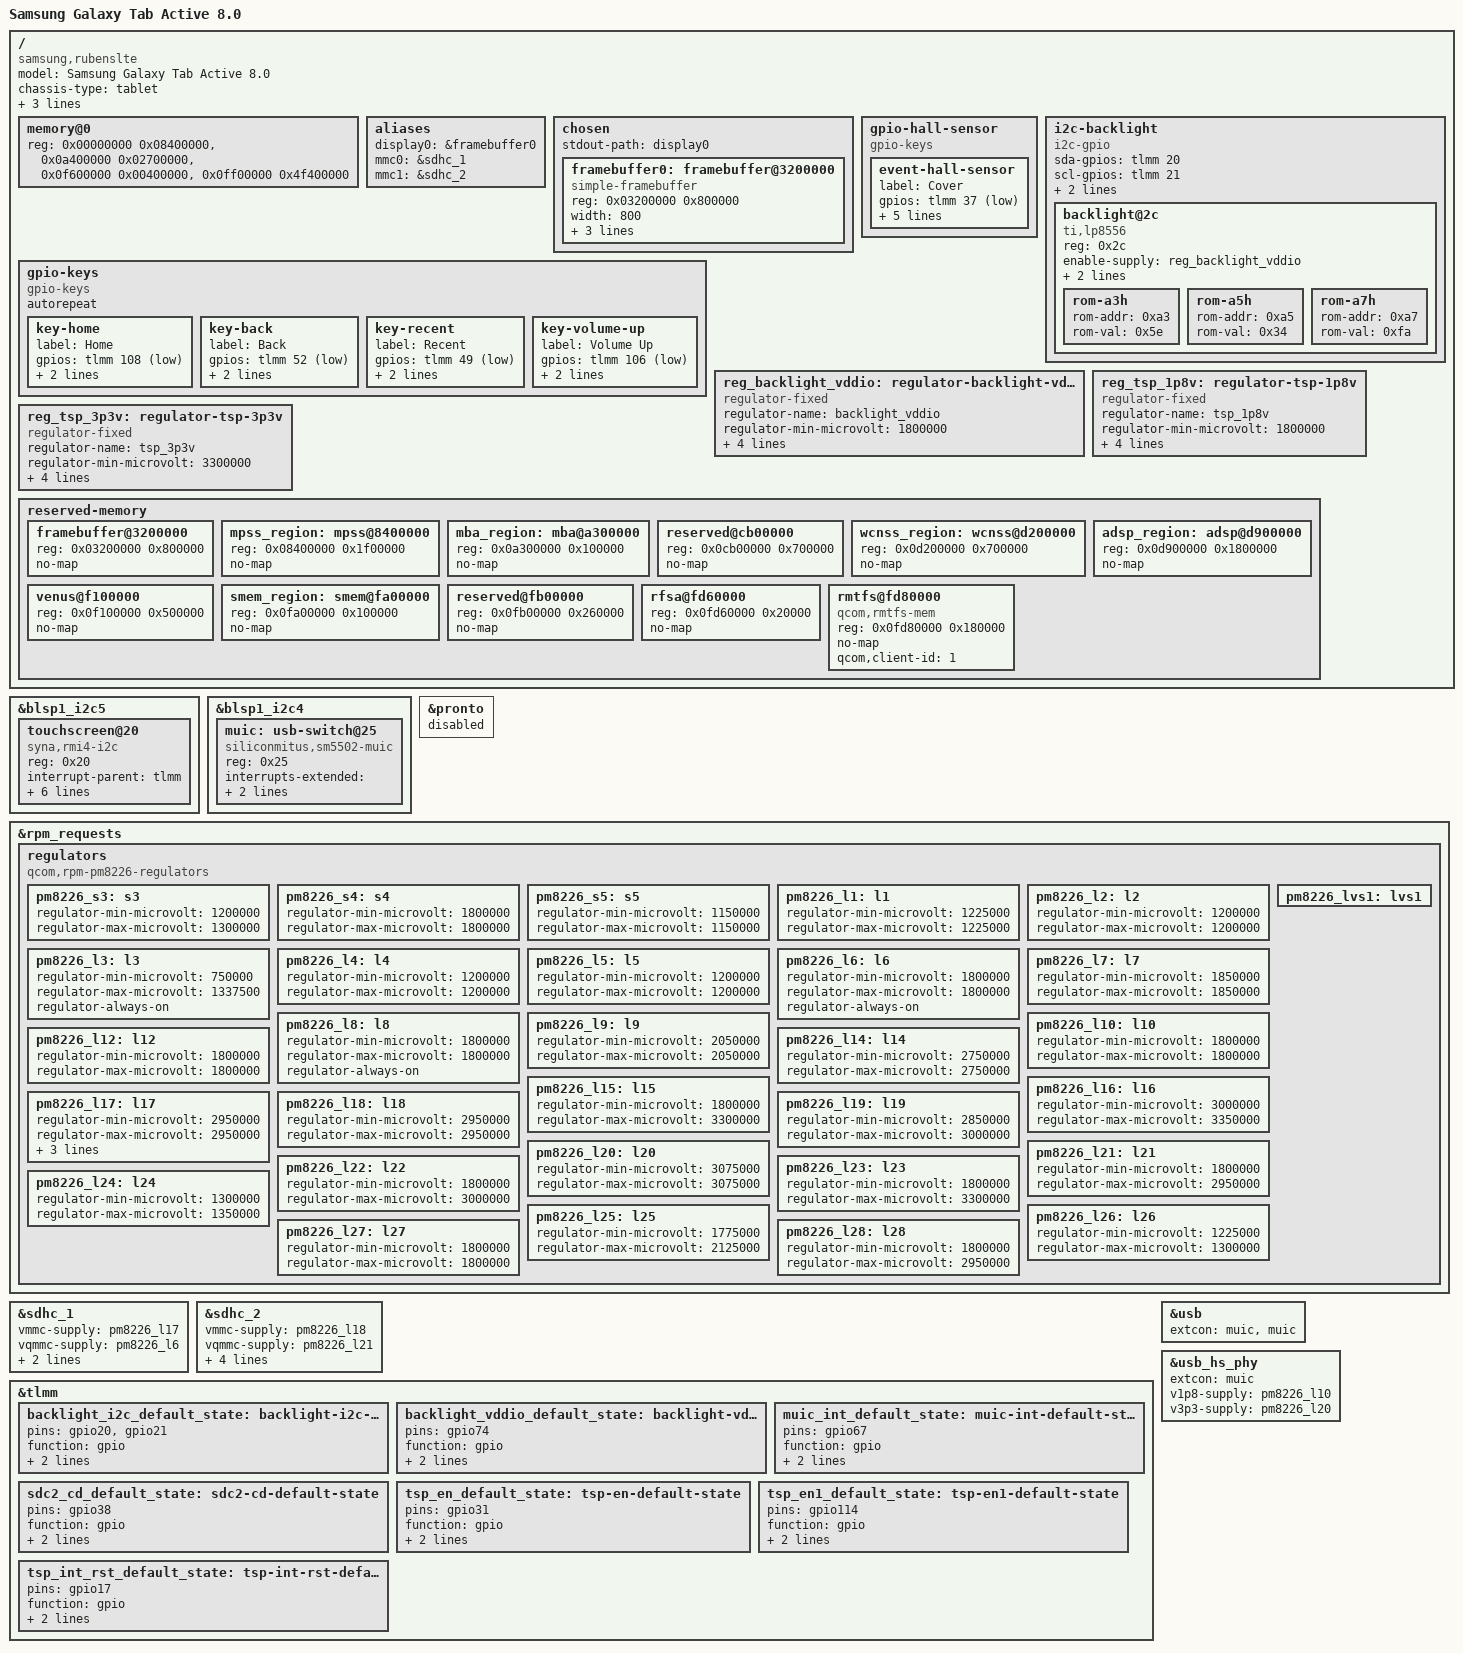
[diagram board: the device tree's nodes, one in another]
// SPDX-License-Identifier: BSD-3-Clause
/*
 * Samsung Galaxy Tab Active 8.0 (SM-T360 / SM-T365), codename "rubens".
 *
 * Derived from qcom-apq8026-samsung-milletwifi.dts (Tab 4 8.0, same APQ8026,
 * same 800x1280 panel class, same LP8556 backlight and touch enables).
 * Device-specific values taken from Samsung's downstream tree:
 *   msm8926-sec-rubenslteeur-r03.dtsi and
 *   dsi_panel_sdc_wxga_video_rubenslte.dtsi
 * and from the running device (dmesg / proc):
 *   panel  mdss_dsi_sdc_wxga_video_lte, 800x1280, S6D7AA0
 *   touch  synaptics rmi4 @ i2c5 0x20, irq gpio17, en gpio31 + gpio114, RUBENS
 *   fb     aboot reserved EBI1 0x800000 @ 0x03200000
 *
 * STATUS: phase 1 (simple-framebuffer + RMI4 touch + eMMC/SD + keys).
 * Not yet compiled - needs a dtc pass in CI. Nodes marked FIXME are unverified.
 */

/dts-v1/;

#include <dt-bindings/gpio/gpio.h>
#include <dt-bindings/input/input.h>
#include <dt-bindings/interrupt-controller/irq.h>
#include "qcom-msm8226.dtsi"
#include "pm8226.dtsi"

/delete-node/ &adsp_region;
/delete-node/ &mba_region;
/delete-node/ &mpss_region;
/delete-node/ &smem_region;
/delete-node/ &wcnss_region;

/ {
	model = "Samsung Galaxy Tab Active 8.0";
	compatible = "samsung,rubenslte", "qcom,apq8026";
	chassis-type = "tablet";

	/*
	 * Copied verbatim from this tablet's factory DTB (RUBENS-WIFI-EUR-OPEN
	 * Rev-02, variant 2). Samsung's aboot matches its QCDT table on these
	 * triples; without the property the bootloader has nothing to match.
	 */
	qcom,msm-id = <0xc708ff01 0x2 0x20000>,
		      <0xc708ff01 0x3 0x20000>,
		      <0xc708ff01 0x4 0x20000>;

	/*
	 * qcom-msm8226.dtsi only carries a placeholder (reg = <0x0 0x0>), so
	 * without this the kernel is told it has no RAM and hangs silently
	 * before printing anything. These four ranges are the System RAM
	 * entries of this tablet's live /proc/iomem, read in TWRP:
	 *   00000000-083fffff  0a400000-0cafffff
	 *   0f600000-0f9fffff  0ff00000-5f2fffff
	 *
	 * The second range must be 0x02700000, not 0x02c00000: the larger size
	 * runs past 0x0cafffff into the wcnss/qseecom reserved regions and the
	 * kernel then owns memory the firmware is still using.
	 */
	memory@0 {
		device_type = "memory";
		reg = <0x00000000 0x08400000>,
		      <0x0a400000 0x02700000>,
		      <0x0f600000 0x00400000>,
		      <0x0ff00000 0x4f400000>;
	};

	aliases {
		display0 = &framebuffer0;
		mmc0 = &sdhc_1; /* SDC1 eMMC slot */
		mmc1 = &sdhc_2; /* SDC2 SD card slot */
	};

	chosen {
		#address-cells = <1>;
		#size-cells = <1>;
		ranges;

		stdout-path = "display0";

		framebuffer0: framebuffer@3200000 {
			compatible = "simple-framebuffer";
			reg = <0x03200000 0x800000>;
			width = <800>;
			height = <1280>;
			stride = <(800 * 3)>;
			format = "r8g8b8";
		};
	};

	gpio-hall-sensor {
		compatible = "gpio-keys";

		event-hall-sensor {
			label = "Cover";
			gpios = <&tlmm 37 GPIO_ACTIVE_LOW>;
			linux,input-type = <EV_SW>;
			linux,code = <SW_LID>;
			debounce-interval = <15>;
			linux,can-disable;
			wakeup-source;
		};
	};

	gpio-keys {
		compatible = "gpio-keys";
		autorepeat;

		key-home {
			label = "Home";
			gpios = <&tlmm 108 GPIO_ACTIVE_LOW>;
			linux,code = <KEY_HOMEPAGE>;
			debounce-interval = <15>;
		};

		key-back {
			label = "Back";
			gpios = <&tlmm 52 GPIO_ACTIVE_LOW>;
			linux,code = <KEY_BACK>;
			debounce-interval = <15>;
		};

		/* KEY_RECENT does not exist upstream; 254 is what Samsung used */
		key-recent {
			label = "Recent";
			gpios = <&tlmm 49 GPIO_ACTIVE_LOW>;
			linux,code = <254>;
			debounce-interval = <15>;
		};

		key-volume-up {
			label = "Volume Up";
			gpios = <&tlmm 106 GPIO_ACTIVE_LOW>;
			linux,code = <KEY_VOLUMEUP>;
			debounce-interval = <15>;
		};

		/*
		 * Volume Down is wired to the PMIC RESIN pin, not a TLMM GPIO
		 * (Samsung comments the node out in the downstream tree), so
		 * there is no gpio-keys entry for it here.
		 */
	};

	i2c-backlight {
		compatible = "i2c-gpio";
		sda-gpios = <&tlmm 20 (GPIO_ACTIVE_HIGH|GPIO_OPEN_DRAIN)>;
		scl-gpios = <&tlmm 21 (GPIO_ACTIVE_HIGH|GPIO_OPEN_DRAIN)>;

		pinctrl-0 = <&backlight_i2c_default_state>;
		pinctrl-names = "default";

		i2c-gpio,delay-us = <4>;

		#address-cells = <1>;
		#size-cells = <0>;

		backlight@2c {
			compatible = "ti,lp8556";
			reg = <0x2c>;
			enable-supply = <&reg_backlight_vddio>;

			dev-ctrl = /bits/ 8 <0x80>;
			init-brt = /bits/ 8 <0x3f>;

			rom-a3h {
				rom-addr = /bits/ 8 <0xa3>;
				rom-val = /bits/ 8 <0x5e>;
			};

			rom-a5h {
				rom-addr = /bits/ 8 <0xa5>;
				rom-val = /bits/ 8 <0x34>;
			};

			rom-a7h {
				rom-addr = /bits/ 8 <0xa7>;
				rom-val = /bits/ 8 <0xfa>;
			};
		};
	};

	reg_backlight_vddio: regulator-backlight-vddio {
		compatible = "regulator-fixed";
		regulator-name = "backlight_vddio";
		regulator-min-microvolt = <1800000>;
		regulator-max-microvolt = <1800000>;

		gpio = <&tlmm 74 GPIO_ACTIVE_HIGH>;
		enable-active-high;

		pinctrl-0 = <&backlight_vddio_default_state>;
		pinctrl-names = "default";
	};

	reg_tsp_1p8v: regulator-tsp-1p8v {
		compatible = "regulator-fixed";
		regulator-name = "tsp_1p8v";
		regulator-min-microvolt = <1800000>;
		regulator-max-microvolt = <1800000>;

		gpio = <&tlmm 114 GPIO_ACTIVE_HIGH>;
		enable-active-high;

		pinctrl-0 = <&tsp_en1_default_state>;
		pinctrl-names = "default";
	};

	reg_tsp_3p3v: regulator-tsp-3p3v {
		compatible = "regulator-fixed";
		regulator-name = "tsp_3p3v";
		regulator-min-microvolt = <3300000>;
		regulator-max-microvolt = <3300000>;

		gpio = <&tlmm 31 GPIO_ACTIVE_HIGH>;
		enable-active-high;

		pinctrl-0 = <&tsp_en_default_state>;
		pinctrl-names = "default";
	};

	reserved-memory {
		#address-cells = <1>;
		#size-cells = <1>;
		ranges;

		framebuffer@3200000 {
			reg = <0x03200000 0x800000>;
			no-map;
		};

		mpss_region: mpss@8400000 {
			reg = <0x08400000 0x1f00000>;
			no-map;
		};

		mba_region: mba@a300000 {
			reg = <0x0a300000 0x100000>;
			no-map;
		};

		reserved@cb00000 {
			reg = <0x0cb00000 0x700000>;
			no-map;
		};

		wcnss_region: wcnss@d200000 {
			reg = <0x0d200000 0x700000>;
			no-map;
		};

		adsp_region: adsp@d900000 {
			reg = <0x0d900000 0x1800000>;
			no-map;
		};

		venus@f100000 {
			reg = <0x0f100000 0x500000>;
			no-map;
		};

		smem_region: smem@fa00000 {
			reg = <0x0fa00000 0x100000>;
			no-map;
		};

		reserved@fb00000 {
			reg = <0x0fb00000 0x260000>;
			no-map;
		};

		rfsa@fd60000 {
			reg = <0x0fd60000 0x20000>;
			no-map;
		};

		rmtfs@fd80000 {
			compatible = "qcom,rmtfs-mem";
			reg = <0x0fd80000 0x180000>;
			no-map;

			qcom,client-id = <1>;
		};
	};
};

/*
 * Touch: Synaptics RMI4 (F12), 1599x2559 sensor reporting 800x1280.
 * Same bus and same enable rails as milletwifi, different controller.
 */
&blsp1_i2c5 {
	status = "okay";

	touchscreen@20 {
		compatible = "syna,rmi4-i2c";
		reg = <0x20>;

		interrupt-parent = <&tlmm>;
		interrupts = <17 IRQ_TYPE_EDGE_FALLING>;

		vdd-supply = <&reg_tsp_1p8v>;
		vio-supply = <&reg_tsp_3p3v>;

		syna,reset-delay-ms = <200>;
		syna,startup-delay-ms = <200>;

		pinctrl-0 = <&tsp_int_rst_default_state>;
		pinctrl-names = "default";
	};
};

/*
 * FIXME: MUIC. rubens uses the same PMIC/charger family as millet, but the
 * exact part and bus were not confirmed from the running device. USB stays
 * dead until this is verified; do not guess further than the sm5502 that the
 * sibling tablet uses.
 */
&blsp1_i2c4 {
	status = "okay";

	muic: usb-switch@25 {
		compatible = "siliconmitus,sm5502-muic";
		reg = <0x25>;

		interrupts-extended = <&tlmm 67 IRQ_TYPE_EDGE_FALLING>;

		pinctrl-0 = <&muic_int_default_state>;
		pinctrl-names = "default";
	};
};

/*
 * WCNSS (WiFi/BT) is left disabled on purpose: it needs the remoteproc
 * firmware pulled off the device's /firmware partition before it can do
 * anything, and upstream support is still WIP.
 */
&pronto {
	status = "disabled";
};

&rpm_requests {
	regulators {
		compatible = "qcom,rpm-pm8226-regulators";

		pm8226_s3: s3 {
			regulator-min-microvolt = <1200000>;
			regulator-max-microvolt = <1300000>;
		};

		pm8226_s4: s4 {
			regulator-min-microvolt = <1800000>;
			regulator-max-microvolt = <1800000>;
		};

		pm8226_s5: s5 {
			regulator-min-microvolt = <1150000>;
			regulator-max-microvolt = <1150000>;
		};

		pm8226_l1: l1 {
			regulator-min-microvolt = <1225000>;
			regulator-max-microvolt = <1225000>;
		};

		pm8226_l2: l2 {
			regulator-min-microvolt = <1200000>;
			regulator-max-microvolt = <1200000>;
		};

		pm8226_l3: l3 {
			regulator-min-microvolt = <750000>;
			regulator-max-microvolt = <1337500>;
			regulator-always-on;
		};

		pm8226_l4: l4 {
			regulator-min-microvolt = <1200000>;
			regulator-max-microvolt = <1200000>;
		};

		pm8226_l5: l5 {
			regulator-min-microvolt = <1200000>;
			regulator-max-microvolt = <1200000>;
		};

		pm8226_l6: l6 {
			regulator-min-microvolt = <1800000>;
			regulator-max-microvolt = <1800000>;
			regulator-always-on;
		};

		pm8226_l7: l7 {
			regulator-min-microvolt = <1850000>;
			regulator-max-microvolt = <1850000>;
		};

		pm8226_l8: l8 {
			regulator-min-microvolt = <1800000>;
			regulator-max-microvolt = <1800000>;
			regulator-always-on;
		};

		pm8226_l9: l9 {
			regulator-min-microvolt = <2050000>;
			regulator-max-microvolt = <2050000>;
		};

		pm8226_l10: l10 {
			regulator-min-microvolt = <1800000>;
			regulator-max-microvolt = <1800000>;
		};

		pm8226_l12: l12 {
			regulator-min-microvolt = <1800000>;
			regulator-max-microvolt = <1800000>;
		};

		pm8226_l14: l14 {
			regulator-min-microvolt = <2750000>;
			regulator-max-microvolt = <2750000>;
		};

		pm8226_l15: l15 {
			regulator-min-microvolt = <1800000>;
			regulator-max-microvolt = <3300000>;
		};

		pm8226_l16: l16 {
			regulator-min-microvolt = <3000000>;
			regulator-max-microvolt = <3350000>;
		};

		pm8226_l17: l17 {
			regulator-min-microvolt = <2950000>;
			regulator-max-microvolt = <2950000>;

			regulator-system-load = <200000>;
			regulator-allow-set-load;
			regulator-always-on;
		};

		pm8226_l18: l18 {
			regulator-min-microvolt = <2950000>;
			regulator-max-microvolt = <2950000>;
		};

		pm8226_l19: l19 {
			regulator-min-microvolt = <2850000>;
			regulator-max-microvolt = <3000000>;
		};

		pm8226_l20: l20 {
			regulator-min-microvolt = <3075000>;
			regulator-max-microvolt = <3075000>;
		};

		pm8226_l21: l21 {
			regulator-min-microvolt = <1800000>;
			regulator-max-microvolt = <2950000>;
		};

		pm8226_l22: l22 {
			regulator-min-microvolt = <1800000>;
			regulator-max-microvolt = <3000000>;
		};

		pm8226_l23: l23 {
			regulator-min-microvolt = <1800000>;
			regulator-max-microvolt = <3300000>;
		};

		pm8226_l24: l24 {
			regulator-min-microvolt = <1300000>;
			regulator-max-microvolt = <1350000>;
		};

		pm8226_l25: l25 {
			regulator-min-microvolt = <1775000>;
			regulator-max-microvolt = <2125000>;
		};

		pm8226_l26: l26 {
			regulator-min-microvolt = <1225000>;
			regulator-max-microvolt = <1300000>;
		};

		pm8226_l27: l27 {
			regulator-min-microvolt = <1800000>;
			regulator-max-microvolt = <1800000>;
		};

		pm8226_l28: l28 {
			regulator-min-microvolt = <1800000>;
			regulator-max-microvolt = <2950000>;
		};

		pm8226_lvs1: lvs1 {};
	};
};

&sdhc_1 {
	vmmc-supply = <&pm8226_l17>;
	vqmmc-supply = <&pm8226_l6>;

	bus-width = <8>;
	non-removable;

	status = "okay";
};

&sdhc_2 {
	vmmc-supply = <&pm8226_l18>;
	vqmmc-supply = <&pm8226_l21>;

	bus-width = <4>;
	cd-gpios = <&tlmm 38 GPIO_ACTIVE_LOW>;

	pinctrl-0 = <&sdhc2_default_state>, <&sdc2_cd_default_state>;
	pinctrl-names = "default";

	status = "okay";
};

&tlmm {
	backlight_i2c_default_state: backlight-i2c-default-state {
		pins = "gpio20", "gpio21";
		function = "gpio";
		drive-strength = <2>;
		bias-disable;
	};

	backlight_vddio_default_state: backlight-vddio-default-state {
		pins = "gpio74";
		function = "gpio";
		drive-strength = <2>;
		bias-disable;
	};

	muic_int_default_state: muic-int-default-state {
		pins = "gpio67";
		function = "gpio";
		drive-strength = <2>;
		bias-disable;
	};

	sdc2_cd_default_state: sdc2-cd-default-state {
		pins = "gpio38";
		function = "gpio";
		drive-strength = <2>;
		bias-disable;
	};

	tsp_en_default_state: tsp-en-default-state {
		pins = "gpio31";
		function = "gpio";
		drive-strength = <2>;
		bias-disable;
	};

	tsp_en1_default_state: tsp-en1-default-state {
		pins = "gpio114";
		function = "gpio";
		drive-strength = <2>;
		bias-disable;
	};

	tsp_int_rst_default_state: tsp-int-rst-default-state {
		pins = "gpio17";
		function = "gpio";
		drive-strength = <10>;
		bias-pull-up;
	};
};

&usb {
	extcon = <&muic>, <&muic>;
	status = "okay";
};

&usb_hs_phy {
	extcon = <&muic>;
	v1p8-supply = <&pm8226_l10>;
	v3p3-supply = <&pm8226_l20>;
};
